# CSI2_PROTOCOL_ENGINE register map
Vendor: Texas Instruments
Registers are 32-bit, access per field, no defined reset value unless marked. A register's access mark holds for its fields unless they carry their own. Offsets are as the file gives them; [hi:lo] are bit positions; {n}, {i} and the like mark numbered series; 'fields as' and 'values as' point back to an identical list.

## CSI2_PROTOCOL_ENGINE (part 2 of 2) — CSI2 protocol engine (MIPI Display Serial Interface Protocole)
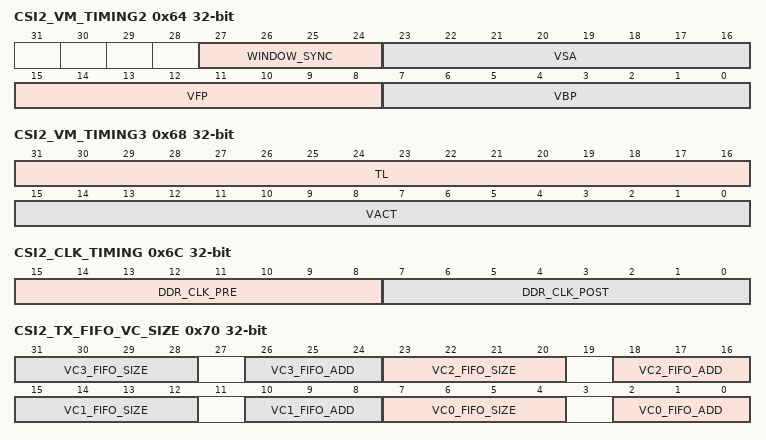
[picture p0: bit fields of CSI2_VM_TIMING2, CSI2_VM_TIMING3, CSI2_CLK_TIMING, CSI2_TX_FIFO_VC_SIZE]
0x64 CSI2_VM_TIMING2 — VIDEO MODE TIMING REGISTER This register defines the video mode timing.
  [27:24] WINDOW_SYNC rw — Number of BYTE clock cycles for the synchronization window. An interrupt for synchronization lost is generated when the received synchornization on video port is not inside the window. CSI2 does not change its own timings if the synch is inside the window. The valid values are from 4 to 15.
  [23:16] VSA rw — Defines the vertical Sync active period used in video mode in number of lines. The supported values are from 0 to 255 It is used to generate the short packet for End of Vertical synchronization.
  [15:8] VFP rw — Defines the vertical front porch used in video mode in number of lines. The supported values are from 0 to 255
  [7:0] VBP rw — Defines the vertical back porch used in video mode in number of lines. The supported values are from 0 to 255
0x68 CSI2_VM_TIMING3 rw — VIDEO MODE TIMING REGISTER This register defines the video mode timing.
  [31:16] TL — Defines the number of length of the line in video mode in number of byte clock cycles (PPI clock) The supported values are from 0 to 8192. The values from 8193 to 65535 are not supported.
  [15:0] VACT — Defines the number of active lines used in video mode. The supported values are from 0 to 65535
0x6C CSI2_CLK_TIMING — CLOCK TIMING REGISTER This register controls the CSI2 Protocol Engine module timers. This register shall not be modified while CSI2_CTRL.IF_EN is set to '1'.
  [15:8] DDR_CLK_PRE rw — Indicates the number of PPI Byte clock cycles between the start of the DDR clock and the assertion of the data request signal. The values from 1 to 255 are valid. The value 0 is reserved. The value is not used if CSI2_CLK_CTRL.DDR_CLK_ALWAYS_ON is set to '1' since the DDR clock is always present.
  [7:0] DDR_CLK_POST rw — Indicates the number of PPI Byte clock cycles after the de-assertion of the data request signal and the stop of the DDR clock. The values from 1 to 255 are valid. The value 0 is reserved. The value is not used if CSI2_CLK_CTRL.DDR_CLK_ALWAYS_ON is set to '1' since the DDR clock is always present.
0x70 CSI2_TX_FIFO_VC_SIZE — Defines the corresponding memory entries allocated for each virtual channel. The virtual channel shall be disabled in order to allocate/un-allocate some entries in the TX FIFO.
  [8n+7:8n+4] VC{n}_FIFO_SIZE rw (n=0..3) — Size of the FIFO allocated for virtual channel {n}.The valid values are from 0 to 8 for a size of the FIFO of 256x33bits corresponding to 0x33bits, 32x33bits, 64x33bits...
  [8n+2:8n] VC{n}_FIFO_ADD rw (n=0..3) — Address of the space allocated in the FIFO for virtual channel {n}.The valid values are from 0 to 7 for a size of the FIFO of 256x33bits corresponding to 0, 32, 64,... for the entry address.
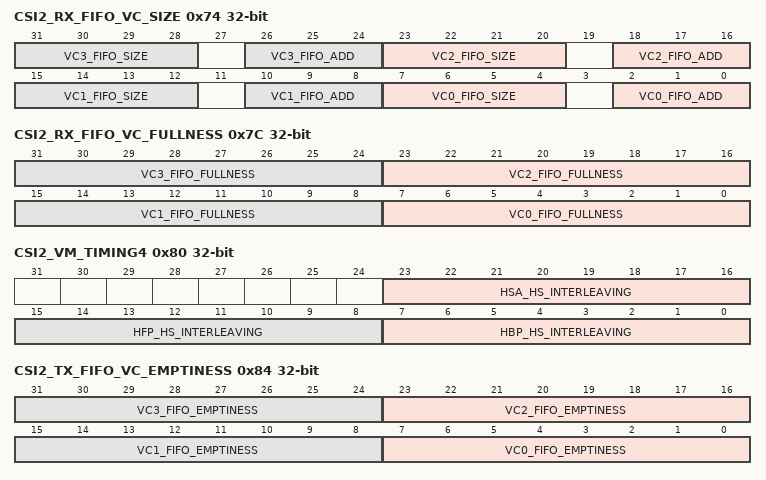
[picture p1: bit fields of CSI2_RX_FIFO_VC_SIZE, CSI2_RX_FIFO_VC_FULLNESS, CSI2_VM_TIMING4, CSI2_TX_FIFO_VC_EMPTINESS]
0x74 CSI2_RX_FIFO_VC_SIZE — Defines the corresponding memory entries allocated for each virtual channel and the addresses. The virtual channel shall be disabled in order to allocate/un-allocate some entries in the RX FIFO.
  fields as CSI2_TX_FIFO_VC_SIZE
0x78 CSI2_COMPLEXIO_CFG2 — COMPLEXIO CONFIGURATION REGISTER for the complex IO This register contains the lane configuration for the ULPS for each lane.
  [17] LP_BUSY ro — Indicates when there are still pending operations for VCs configured for LP mode. Forced to 1 when at least one VC is enabled and configured for LP mode.
    0=FALSE (LP logic is idle); 1=TRUE (LP logic is active)
  [16] HS_BUSY ro — Indicates when there are still pending operations for VCs configured for HS mode. Forced to 1 when at least one VC is enabled and configured for HS mode.
    0=FALSE (HS logic is idle); 1=TRUE (HS logic is active)
  [9] LANE5_ULPS_SIG2 rw — Enables the ULPS for the lane #5. The HW shall change the state of the lane to ULPS only when it is in stop state and there is no data pending inside the CSI2 protocol engine and the CSI2 protocol engine has control of the bus (BTA has not been sent). The state of the signal TxRequestEsc is changed if lane #5 is a data lane. The state of the signal TxUlpsClk is changed if lane #5 is a clock lane. There will be a latency depending on the frequency of TxClkExc. This bit should be read back to confirm a write has been effective.
    0=INACTIVE (READ:Inactive state effective. WRITE: Request to change to inactive state); 1=ACTIVE (READ:Active state effective. WRITE: Change request to active. If the lane is a data lane, TxRequestEsc is asserted and synchronously TxUlpsEsc is asserted for one period of TxClkEsc.)
  [n+4] LANE{n}_ULPS_SIG2 rw (n=1..4) — Enables the ULPS for the lane #{n}. The HW shall change the state of the lane to ULPS only when it is in stop state and there is no data pending inside the CSI2 protocol engine and the CSI2 protocol engine has control of the bus (BTA has not been sent). The state of the signal TxRequestEsc is changed if lane #{n} is a data lane. The state of the signal TxUlpsClk is changed if lane #{n} is a clock lane. There will be a latency depending on the frequency of TxClkExc. This bit should be read back to confirm a write has been effective.
    0=INACTIVE (READ: Inactive state effective. WRITE: Request to change to inactive state); 1=ACTIVE (READ:Active state effective. WRITE: Change request to active. If the lane is a data lane, TxRequestEsc is asserted and synchronously TxUlpsEsc is asserted for one period of TxClkEsc.)
  [4] RESERVED3 ro — Write 0's for future compatibility. Reads returns 0.
  [4] LANE5_ULPS_SIG1 rw — Enables the ULPS for the lane #5. The HW shall change the state of the lane to ULPS only when it is in stop state and there is no data pending inside the CSI2 protocol engine and the CSI2 protocol engine has control of the bus (BTA has not been sent). The state of the signal TxULPSExit is changed if the lane #5 is a clock lane. There will be a latency depending on the frequency of TxClkExc. This bit should be read back to confirm a write has been effective.
    0=INACTIVE (READ:Inactive state effective. WRITE: Request to change to inactive state); 1=ACTIVE (READ:Active state effective. WRITE: Change request to active. If the lane is a data lane, TxRequestEsc is asserted and synchronously TxUlpsEsc is asserted for one period of TxClkEsc)
  [3] LANE4_ULPS_SIG1 rw — Enables the ULPS for the lane #4. The HW shall change the state of the lane to ULPS only when it is in stop state and there is no data pending inside the CSI2 protocol engine and the CSI2 protocol engine has control of the bus (BTA has not been sent). The state of the signal TxULPSExit is changed if the lane #4 is a clock lane. There will be a latency depending on the frequency of TxClkExc. This bit should be read back to confirm a write has been effective.
    0=INACTIVE (READ: Inactive state effective. WRITE: Request to change to inactive state); 1=ACTIVE (READ:Active state effective. WRITE: Change request to active. If the lane is a data lane, TxRequestEsc is asserted and synchronously TxUlpsEsc is asserted for one period of TxClkEsc)
  [2] LANE3_ULPS_SIG1 rw — Enables the ULPS for the lane #3. The HW shall change the state of the lane to ULPS only when it is in stop state and there is no data pending inside the CSI2 protocol engine and the CSI2 protocol engine has control of the bus (BTA has not been sent). The state of the signal TxULPSExit is changed if the lane #3 is a clock lane. There will be a latency depending on the frequency of TxClkExc. This bit should be read back to confirm a write has been effective.
    values as LANE4_ULPS_SIG1
  [1] LANE2_ULPS_SIG1 rw — Enables the ULPS for the lane #2. The HW shall change the state of the lane to ULPS only when it is in stop state and there is no data pending inside the CSI2 protocol engine and the CSI2 protocol engine has control of the bus (BTA has not been sent). The state of the signal TxULPSExit is changed if the lane #2 is a clock lane. There will be a latency depending on the frequency of TxClkExc. This bit should be read back to confirm a write has been effective.
    values as LANE4_ULPS_SIG1
  [0] LANE1_ULPS_SIG1 rw — Enables the ULPS for the lane #1. The HW shall change the state of the lane to ULPS only when it is in stop state and there is no data pending inside the CSI2 protocol engine and the CSI2 protocol engine has control of the bus (BTA has not been sent). The state of the signal TxULPSExit is changed if the lane #1 is a clock lane. There will be a latency depending on the frequency of TxClkExc. This bit should be read back to confirm a write has been effective.
    0=INACTIVE (READ:Inactive state effective. WRITE: Request to change to inactive state); 1=ACTIVE (READ:Active state effective WRITE: Change request to active. If the lane is a data lane, TxRequestEsc is asserted and synchronously TxUlpsEsc is asserted for one period of TxClkEsc)
0x7C CSI2_RX_FIFO_VC_FULLNESS ro — Defines the fullness of each space allocated for each virtual channel.
  [8n+7:8n] VC{n}_FIFO_FULLNESS (n=0..3) — Fullness of the FIFO allocated for virtual channel {n}.The valid values are from 0 to CSI2_GNQ.RX_FIFODEPTH-1 corresponding to 1x33-bit,...up to CSI2_GNQ.RX_FIFODEPTH x33-bit.
0x80 CSI2_VM_TIMING4 — VIDEO MODE TIMING REGISTER This register defines the video mode timing.
  [23:16] HSA_HS_INTERLEAVING rw — Defines the number of HS byte clock cycles that can be used for interleaving High Speed command mode packet into Video Mode stream during HSA blanking period. The supported values are from 0 to 255.
  [15:8] HFP_HS_INTERLEAVING rw — Defines the number of HS byte clock cycles that can be used for interleaving High Speed command mode packet into Video Mode stream during HFP blanking period. The supported values are from 0 to 255
  [7:0] HBP_HS_INTERLEAVING rw — Defines the number of HS byte clock cycles that can be used for interleaving High Speed command mode packet into Video Mode stream during HBP blanking period. The supported values are from 0 to 255
0x84 CSI2_TX_FIFO_VC_EMPTINESS ro — Defines the emptiness of each space allocated for each virtual channel.
  [8n+7:8n] VC{n}_FIFO_EMPTINESS (n=0..3) — Emptiness of the FIFO allocated for virtual channel {n}.The valid values are from 0 to CSI2_GNQ.TX_FIFODEPTH-1 corresponding to 1x33-bit,...up to CSI2_GNQ.TX_FIFODEPTH x33-bit.
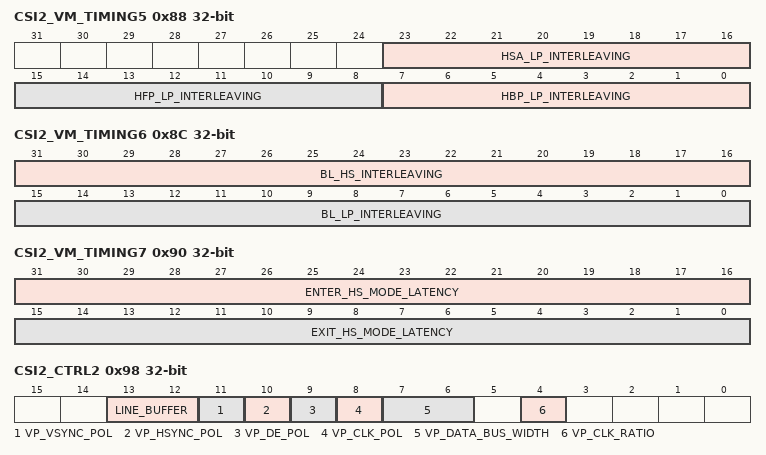
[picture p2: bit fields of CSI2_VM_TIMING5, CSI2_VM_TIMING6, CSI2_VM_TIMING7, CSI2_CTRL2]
0x88 CSI2_VM_TIMING5 — VIDEO MODE TIMING REGISTER This register defines the video mode timing.
  [23:16] HSA_LP_INTERLEAVING rw — Defines the number of bytes of Low Power command mode packets that can be sent on PPI link during HSA blanking period. The supported values are from 0 to 255.
  [15:8] HFP_LP_INTERLEAVING rw — Defines the number of bytes of Low Power command mode packets that can be sent on PPI link during HFP blanking period. The supported values are from 0 to 255
  [7:0] HBP_LP_INTERLEAVING rw — Defines the number of bytes of Low Power command mode packets that can be sent on PPI link during HBP blanking period. The supported values are from 0 to 255
0x8C CSI2_VM_TIMING6 rw — VIDEO MODE TIMING REGISTER This register defines the video mode timing.
  [31:16] BL_HS_INTERLEAVING — Defines the number of HS byte clock cycles that can be used for interleaving High Speed command mode packet into Video Mode stream during blanking periods during VSA, VBP, VFP periods inside one video frame on PPI link. The supported values are from 0 to 65535 .
  [15:0] BL_LP_INTERLEAVING — Defines the maximum number of bytes of Low Power command mode packets that can be sent on PPI link during blanking periods during VSA, VBP or VFP periods inside one video frame on PPI link. The supported values are from 0 to 65535
0x90 CSI2_VM_TIMING7 rw — Defines the minimum number of HS bytes clock cycles that are required to allow for the delays in entering and exiting HS mode. The supported values are from 0 to 65535
  [31:16] ENTER_HS_MODE_LATENCY — Defines the number of HS byte clock cycles necessary for entering to HS mode. It corresponds to the delay in number of HS clock cycles from assertion of TxRequestHS signal to 1 until assertion of TxReadyHS signal to 1. The supported values are from 0 to 65535 .
  [15:0] EXIT_HS_MODE_LATENCY — Defines the number of HS byte clock cycles necessary for exiting from HS mode. It corresponds to the maximum delay in number of HS byte clock from de-assertion of TxRequestHS signal until PPI link is in LP-11 state from which a new entrance to HS mode can be initiated which does not take more than ENTER_HS_MODE_LATENCY clock cycles. The supported values are from 0 to 65535
0x94 CSI2_STOPCLK_TIMING — Number of functional clock cycles to wait for TxByteClkHS to stop/start after change in CSI2StopClk signal
  [7:0] CSI2_STOPCLK_LATENCY rw — Clock gating latency from CSI2 Protocol to TxByteClkHS
0x98 CSI2_CTRL2 — Additional control bits for use with Video Port 2
  [13:12] LINE_BUFFER rw — Number of line buffers to be used while receiving data on the video port. The valid values are from 0 to CSI2_GNQ.VP2_NB_LINE_BUFFER.
    0=F0 (No line buffer); 1=F1 (1 line buffer); 2=F2 (2 line buffers)
  [11] VP_VSYNC_POL rw — VP vertical synchronization signal polarity
    0=LOW (VSYNC signal on the video port is active low.); 1=HIGH (VSYNC signal on the video port is active high.)
  [10] VP_HSYNC_POL rw — VP horizontal synchronization signal polarity
    0=LOW (HSYNC signal on the video port is active low.); 1=HIGH (HSYNC signal on the video port is active high.)
  [9] VP_DE_POL rw — VP data enable signal polarity
    0=LOW (DE signal on the video port is active low.); 1=HIGH (DE signal on the video port is active high.)
  [8] VP_CLK_POL rw — VP clock polarity
    0=FALLING (The CSI2 Protocol Engine module captures the data on the VP on the pixel clock falling edge. The module connected to the VP shall drive the data on the pixel clock rising edge.); 1=RISING (The CSI2 Protocol Engine module captures the data on the VP on the pixel clock raising edge. The module connected to the VP shall drive the data on the pixel clock falling edge.)
  [7:6] VP_DATA_BUS_WIDTH rw — Defines the size of the video port data bus
    0=F16 (16-bits data width (LSB of the 24-bit video port data bus)); 1=F18 (18-bits data width (LSB of the 24-bit video port data bus)); 2=F24 (24-bits data width (LSB of the 24-bit video port data bus))
  [4] VP_CLK_RATIO rw — The field indicates the clock ratio between VP.CLK and VP.PCLK. The clock VP.PCLK is generated from VP.CLK. It is divided down. The information is only used when the video port is used to provide data in command mode. In the case of video mode, it is not used.
    0=RATIO2 (The clock VP.PCLK is the clock VP.CLK divided by 2. The duty cycle of VP.PCLK is 50/50.); 1=RATIO3ANDHIGHER (The clock VP.PCLK is the clock VP.CLK divided by 3 or more. The duty cycle of VP.PCLK is not 50/50 for odd ratio numbers (3,5,7,...).)
0x9C CSI2_VM_TIMING8 — VIDEO MODE TIMING REGISTER This register defines the video mode timing.
  [1:0] HFPX rw — Extension to the HFP register. Additional bits added to MSB.
0xA0 CSI2_TE_HSYNC_WIDTH_0 — The register configures the TE HSYNC minimum pulse width for TE0 and TE1 CMOS signals The input TE signal is asynchronous and needs to be re-synchronizred to CSI2_CLK clock domain.
  [19:8] MIN_HSYNC_PULSE_WIDTH rw — Programmable min HSYNC pulse width Minimum HSYNC pulse width. Number of CSI2_CLK clock cycles times 256 to determine when HSYNC pulse occurs. The value 0 is invalid.
0xA4 CSI2_TE_VSYNC_WIDTH_0 — The register configures the TE VSYNC minimum pulse width for TE0 and TE1 CMOS signals The input TE signal is asynchronous and needs to be re-synchronizred to CSI2_CLK clock domain.
  [19:8] MIN_VSYNC_PULSE_WIDTH rw — Programmable min VSYNC pulse width Minimum VSYNC pulse width. Number of CSI2_CLK cycles times 256 to determine when VSYNC pulse occurs. The value 0 is invalid. The value shall be greater than MIN_HSYNC_PULSE_WIDTH when CSI2_TE_HSYNC_NUMBER is greather than 0
0xA8 CSI2_TE_HSYNC_NUMBER_0 — The register configures the number of HSYNC to synchronize the beginning of the transfer on CSI2 link based on the number of HSYNC pulse received on the TE line. The input TE signal is asynchronous and needs to be re-synchronizred to CSI2_CLK clock domain.
  [10:0] LINE_NUMBER rw — Programmable line number Line number from 0 to 2047. Number of HSYNC after the VSYNC occurs before the beginning of the transfer. Any HSYNC before VSYNC is ignored.
0xAC CSI2_TE_HSYNC_WIDTH_1 — The register configures the TE HSYNC minimum pulse width for TE0 and TE1 CMOS signals The input TE signal is asynchronous and needs to be re-synchronizred to CSI2_CLK clock domain.
  fields as CSI2_TE_HSYNC_WIDTH_0
0xB0 CSI2_TE_VSYNC_WIDTH_1 — The register configures the TE VSYNC minimum pulse width for TE0 and TE1 CMOS signals The input TE signal is asynchronous and needs to be re-synchronizred to CSI2_CLK clock domain.
  fields as CSI2_TE_VSYNC_WIDTH_0
0xB4 CSI2_TE_HSYNC_NUMBER_1 — The register configures the number of HSYNC to synchronize the beginning of the transfer on CSI2 link based on the number of HSYNC pulse received on the TE line. The input TE signal is asynchronous and needs to be re-synchronizred to CSI2_CLK clock domain.
  fields as CSI2_TE_HSYNC_NUMBER_0
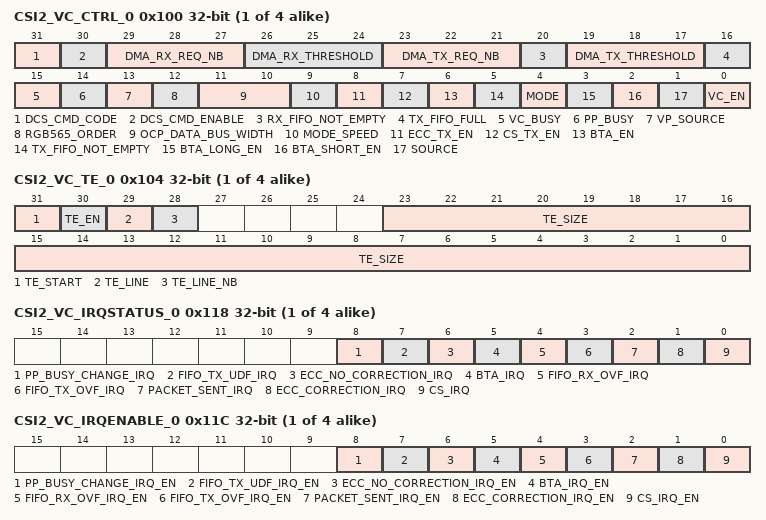
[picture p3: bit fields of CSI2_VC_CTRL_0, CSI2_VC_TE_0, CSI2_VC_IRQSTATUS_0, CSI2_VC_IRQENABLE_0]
{0x100+0x20*i} CSI2_VC_CTRL_{i} (i=0..3) — CONTROL REGISTER - Virtual channel This register controls the virtual channel.
  [31] DCS_CMD_CODE rw — DCS command code value to insert between header and video port or OCP slave data when enabled by DCS_CMD_ENABLE (only when TE mechanism is not used otherwise the bit-field DCS_CMD_CODE is ignored by CSI2 protocol engine).
    0=DCS_CONTINUE (DCS write memory continue code is inserted.); 1=DCS_START (DCS write memory start code is inserted.)
  [30] DCS_CMD_ENABLE rw — Enables automatic insertion of DCS command codes when data is sourced by the video port.
    0=DCS_DISABLE (DCS command code is NOT inserted when command mode traffic is coming from the Video Port or OCP slave port.); 1=DCS_ENABLE (DCS command code is inserted automatically when command mode traffic is coming from the Video Port or OCP slave port.)
  [29:27] DMA_RX_REQ_NB rw — Selection of the use of the DMA request (associated to the RX FIFO)
    0=DMA_REQ0 (DMA_req0 is selected (valid only if CSI2_GNQ.NB_DMA_REQUEST is greater than 0)); 1=DMA_REQ1 (DMA_req1 is selected (valid only if CSI2_GNQ.NB_DMA_REQUEST is greater than 1)); 2=DMA_REQ2 (DMA_req2 is selected (valid only if CSI2_GNQ.NB_DMA_REQUEST is greater than 2)); 3=DMA_REQ3 (DMA_req3 is selected (valid only if CSI2_GNQ.NB_DMA_REQUEST is equal to 3)); 4=NO_DMA_REQ (No DMA req selected)
  [26:24] DMA_RX_THRESHOLD rw — Defines the threshold value for the DMA request (associated to the RX FIFO)
    0=F1 (1x 32 bits); 1=F2 (2 x 32 bits); 2=F4 (4 x 32 bits); 3=F8 (8 x 32 bits); 4=F16 (16 x 32 bits); 5=F32 (32 x 32 bits)
  [23:21] DMA_TX_REQ_NB rw — Selection of the use of the DMA request (associated to the TX FIFO)
    values as DMA_RX_REQ_NB
  [20] RX_FIFO_NOT_EMPTY ro — FIFO status
    0=EMPTY (The RX FIFO is empty (the FIFO does not contain any data for the virtual channel)); 1=NOT_EMPTY (The RX FIFO is not empty (the FIFO contains at least one byte for the virtual channel))
  [19:17] DMA_TX_THRESHOLD rw — Defines the threshold value for the DMA request (associated to the TX FIFO)
    values as DMA_RX_THRESHOLD
  [16] TX_FIFO_FULL ro — FIFO status
    0=NOT_FULL (The TX FIFO is not full (the FIFO can accept at least one more 32-bit valuel)); 1=FULL (The TX FIFO is full)
  [15] VC_BUSY ro — Indicates if previously scheduled activities (packets, BTA) are still being processed. Forced to 1 if VC is enabled. Software should check this bit is 0 before changing channel configuration.
    0=COMPLETED (No pending operations for this VC); 1=BUSY (Pending operations for this VC)
  [14] PP_BUSY ro — Ping-pong buffer busy status.
    0=PP_FREE (Software is permitted to write a new header for VP command mode traffic.); 1=PP_BUSY (Software is NOT permitted to write a new header for VP command mode traffic.)
  [13] VP_SOURCE rw — Selection between video port 1 and video port 2. If CSI2_GNQ.NB_VIDEO_PORTS=0, the bit-field is ignored since only video port 1 is present.
    0=VIDEO_PORT_1 (The video port 1 is selected.); 1=VIDEO_PORT_2 (The video port 2 is selected.)
  [12] RGB565_ORDER rw — Byte order for RBG565
    0=RGB565_DBI2 (Byte order as documented in the MIPI DBI-2 spec); 1=RGB565_VIDEO (Byte order as for video mode)
  [11:10] OCP_DATA_BUS_WIDTH rw — Defines the size of the OCP data bus
    0=F16 (16-bits data width (LSB of the 32-bit OCP port data bus)); 1=F24 (24-bits data width (LSB of the 32-bit OCP port data bus)); 2=F1616 (2x16-bits data width (first pixel on the LSB of the 32-bit OCP port data bus and second pixel on the MSB of the 32-bit OCP port data bus for the same OCP access)); 3=F32 (32-bits data width)
  [9] MODE_SPEED rw — Selection of the mode. The information is used by HW only if MODE=COMMAND_MODE otherwise it is ignored.
    0=LP (Low power mode (CMOS) is used to send short and long packets to the peripheral.); 1=HS (High Speed mode (SLVS) is used to send short and long packets to the peripheral.)
  [8] ECC_TX_EN rw — Enables the Error Correction Code generation for the transmit header (short and long packets).
    0=DISABLE (Disabled); 1=ENABLE (Enabled)
  [7] CS_TX_EN rw — Enables the checksum generation for the transmit payload (long packet only).
    0=DISABLE (Disabled. The value 0x00 is used.); 1=ENABLE (Enabled. The Check-sum value is calculated by HW.)
  [6] BTA_EN rw — Send the bus turn around to the peripheral. It can be used when the automatic mode is enabled (BTA_SHORT_EN=1 or/and BTA_LONG_EN=1). In that case only one BTA is sent to the peripheral. The manual mode is used to allow the user to define for which packets, the turn around is required for example getting acknowledge from the peripheral.
    0=DISABLE (READS: BTA generation is completed. It is reset by HW when it is completed. WRITES: Cancellation of the BTA generation (not guarantee since it could already on going, shall not be used).); 1=ENABLE (READS: BTA generation has been requested by user (it could be on going but not completed). WRITES: Request for BTA generation.)
  [5] TX_FIFO_NOT_EMPTY ro — FIFO status
    0=EMPTY (The TX FIFO is empty (the FIFO does not contain any data for the virtual channel)); 1=NOT_EMPTY (The TX FIFO is not empty (the FIFO contains at least one byte for the virtual channel))
  [4] MODE rw — Selection of the mode
    0=COMMAND_MODE; 1=VIDEO_MODE (Video mode. The bit-fields MODE_SPEED and SOURCE are not used by HW. The bit-field VP_SOURCE is used to select between video port 1 and video port 2 when two video ports are present.)
  [3] BTA_LONG_EN rw — Enables the automatic bus turn-around after completion of each long packet transmission.
    0=DISABLE (Disabled); 1=ENABLE (Enabled)
  [2] BTA_SHORT_EN rw — Enables the automatic bus turn-around after completion of each short packet transmission.
    0=DISABLE (Disabled); 1=ENABLE (Enabled)
  [1] SOURCE rw — Selection of the source between OCP and the Video port(s) (used by the HW only if MODE=COMMAND MODE (0x0) otherwise it is ignored). The number of available video ports is defined in CSI2_GNQ.NB_VIDEO_PORTS.
    0=OCP_SLAVE_PORT (All the data are provided by the slave port. Any transfer on the video port is ignored for this virtual channel.); 1=VIDEO_PORT (If MODE=VIDEO_MODE. the data received on the video port 1 or video port 2, selected using VP_SOURCE (pixels and enabled synchronization events using CSI2_CTRL1.VP_HSYNC_START, CSI2_CTRL1.VP_HSYNC_END, CSI2_CTRL1.VP_VSYNC_START, CSI2_CTRL1.VP_VSYNC_END for video port 1 and CSI2_CTRL2.VP_HSYNC_START, CSI2_CTRL2.VP_HSYNC_END, CSI2_CTRL2.VP_VSYNC_START, CSI2_CTRL2.VP_VSYNC_END for video port 2) are sent on the virtual channel (only one virtual channel can be associated with the video port, it is the SW responsibility to ensure that no more than one virtual channel is enabled with the video port as the main source for data). If MODE=COMMAND_MODE, the VP.STALL signal is used by the protocol engine to indicate when new data are required. The synchronization signals are not generated by the display controller. Regardless of the MODE, no data can be provided on the OCP slave port.)
  [0] VC_EN rw — Enables the virtual channel.
    0=DISABLE (Disabled. The virtual channel shall be disabled for any register change in the CSI2_VC_... registers the corresponding virtual channel id (except for setting the bit-fields/registers: CSI2_VC_CTRL.BTA_EN, CSI2_VC_TE.TE_SIZE, CSI2_VC_TE.TE_START, CSI2_VC_LONG_,,, CSI2_VC_SHORT_..., CSI2_VC_IRQ...).); 1=ENABLE (Enabled. No change is allowed to the virtual channel registers expect resetting the VC_EN.)
{0x104+0x20*i} CSI2_VC_TE_{i} (i=0..3) — CONTROL REGISTER - Virtual channel This register controls the tearing effect logic. It defines the size of the transfer when TE occurs and enables the automatic TE mode.
  [31] TE_START rw — Manual control of the start of the transfer. The user can use the TE interrupt in order to know that the TE trigger has been received prior to set the TE_START bit-field. It is not mandatory to use the TE interrupt.
    0=DISABLE (Indicates the end of the transfer. The bit can be used by user to cancel the transfer if not already started. The FIFO shall be flushed by SW to ensure there is no data remaining in it.); 1=ENABLE (Starts the transfer of the data. The size is defined in TE_SIZE. The bit-field is set until the transfer is completed. It is reset by HW when the transfer is completed.)
  [30] TE_EN rw — Tearing Effect Control
    0=DISABLE (Disables the automatic transfer. The user shall use the interruption in order to know when TE PHY trigger is received or when the TE is detected on the input CMOS signals. The HW reset the bit-field when the transfer is completed (TE_SIZE=0).); 1=ENABLE (Enables the automatic transfer of the data using the TE PHY trigger or one of the TE input signals as a synchronization event. The bit-field TE_LINE defines if the CMOS signal is used or if the PHY trigger is used.)
  [29] TE_LINE rw
    0=DISABLE (Disabled the TE CMOS signalling for the automatic data transfer. The CSI2 PHY trigger is used for the automactic data transfer.); 1=ENABLE (Enables the TE CMOS signalling for the automatic data transfer. The CSI2 PHY trigger is not used for the automactic data transfer.)
  [28] TE_LINE_NB rw — Selection between TE0 and TE1 cmos signals.
    0=TE0 (TE0 cmos input line is selected); 1=TE1 (TE1 cmos input line is selected)
  [23:0] TE_SIZE rw — Defines the number of byte (payload data excluding the check -sum) to be sent. The write into the register CSI2_VC_LONG_PACKET_HEADER shall be performed by the user before sending data from the register CSI2_VC_LONG_PACKET_PAYLOAD. The register value is decremented for every byte sent of the CSI2 link. At the end of the transfer (TE_SIZE=0), the bit-field TE_EN is reset by HW. The DMA_request shall be asserted when the trigger is received in order to receive data in the TX FIFO. It shall not be used until all data (TE_SIZE) have been received in the FIFO.
{0x108+0x20*i} CSI2_VC_LONG_PACKET_HEADER_{i} wo (i=0..3) — LONG PACKET HEADER INFORMATION -Virtual channel This register sets the 32-bit DATA_ID + Word count + ECC (the virtual channel id can be different than VC). The ECC will be computed if ECC_TX_EN is set to 1. DATA_ID is located at bit[7:0] WC is located at bit[23:8] ECC is located at bit[31:24] (Least significant byte first and least significant bit first)
  [31:0] HEADER — Packet header information: DATA ID + DATA FIELD +ECC
{0x10C+0x20*i} CSI2_VC_LONG_PACKET_PAYLOAD_{i} wo (i=0..3) — LONG PACKET PAYLOAD INFORMATION -Virtual channel This register sets the payload information (excluding Check-sum). The HW shall capture the word count in the packet header (in CSI2_VC_LONG_PACKET_HEADER) in order to determine the last valid data. (the virtual channel id can be different than VC). Byte1 is bit[7:0] Byte2 is bit[15:8] Byte3 is bit[23:16] Byte4 is bit[31:24] Byten is sent before Byten+1 (Least significant byte first and least significant bit first)
  [31:0] PAYLOAD — Packet payload information (excluding check-sum)
{0x110+0x20*i} CSI2_VC_SHORT_PACKET_HEADER_{i} rw (i=0..3) — SHORT PACKET HEADER INFORMATION -Virtual channel This register sets the 24-bit DATA_ID + Short Packet Data Field + ECC (the virtual channel id can be different than VC). The ECC will be computed if ECC_TX_EN is set to 1. DATA_ID is located at bit[7:0] Short Packet Data field is located at bit[23:8] ECC is located at bit[31:24] (Least significant byte first and least significant bit first)
  [31:0] HEADER — WRITES: Packet header information: DATA ID + DATA FIELD +ECC written into the TX FIFO READS: 32-bit values read from the RX FIFO
{0x118+0x20*i} CSI2_VC_IRQSTATUS_{i} (i=0..3) — INTERRUPT STATUS REGISTER - Virtual channel This register regroups all the events related to the virtual channel.
  [all] fields
    0=FALSE (READS: Event is false. WRITES: Status bit unchanged.); 1=TRUE (READS: Event is true (pending). WRITES: Status bit is reset.)
  [8] PP_BUSY_CHANGE_IRQ rw — Video Port ping-pong buffer busy status. PP_BUSY has changed from 1 to 0.
  [7] FIFO_TX_UDF_IRQ rw — FIFO underflow status. The FIFO used on the slave port for buffering the data received on the OCP slave port for the virtual channel has underflowed which means that the data for the current packet have not been received in time since the transfer of the packet are already started (transfer started since the packet size is bigger than space allocated in the FIFO).
  [6] ECC_NO_CORRECTION_IRQ rw — ECC error status (short and long packets). No correction of the header because of more than 1-bit error.
  [5] BTA_IRQ rw — Virtual channel - BTA status.
  [4] FIFO_RX_OVF_IRQ rw — FIFO overflow error status. The FIFO used on the slave port for buffering the data received on the CSI2 link for the virtual channel has overflowed.
  [3] FIFO_TX_OVF_IRQ rw — FIFO overflow error status. The FIFO used on the slave port for buffering the data received on the OCP slave port for the virtual channel has overflowed.
  [2] PACKET_SENT_IRQ rw — Indicates that a packet has been sent. It is used when BTA manual mode is used.
  [1] ECC_CORRECTION_IRQ rw — Virtual channel - ECC has been used to do the correction of the only 1-bit error status (short and long packet).
  [0] CS_IRQ rw — Virtual channel - Check-Sum mismatch status.
{0x11C+0x20*i} CSI2_VC_IRQENABLE_{i} (i=0..3) — INTERRUPT ENABLE REGISTER - Virtual channel This register regroups all the events related to virtual channel.
  [all] fields
    0=DISABLE (Event is masked); 1=ENABLE (Event generates an interrupt when it occurs)
  [8] PP_BUSY_CHANGE_IRQ_EN rw — Video Port ping-pong buffer busy status.
  [7] FIFO_TX_UDF_IRQ_EN rw — FIFO underflow enable. The FIFO used on the slave port for buffering the data received on the OCP slave port for the virtual channel has underflowed which means that the data for the current packet have not been received in time since the transfer of the packet are already started (transfer started since the packet size is bigger than space allocated in the FIFO).
  [6] ECC_NO_CORRECTION_IRQ_EN rw — ECC error (short and long packets). No correction of the header because of more than 1-bit error.
  [5] BTA_IRQ_EN rw — Virtual channel -Bus turn around reception
  [4] FIFO_RX_OVF_IRQ_EN rw — FIFO overflow enable. The FIFO used on the slave port for buffering the data received on the CSI2 link for the virtual channel has overflowed.
  [3] FIFO_TX_OVF_IRQ_EN rw — FIFO overflow enable. The FIFO used on the slave port for buffering the data received on the OCP slave port for the virtual channel has overflowed.
  [2] PACKET_SENT_IRQ_EN rw — Indicates that a packet has been sent. It is used when BTA manual mode is used.
  [1] ECC_CORRECTION_IRQ_EN rw — Virtual channel - ECC has been used to correct the only 1-bit error (short and long packet).
  [0] CS_IRQ_EN rw — Virtual channel - Check-Sum of the payload mismatch detection
